# ATSAMG54G19 device description
Architecture: CORTEX-M4; Family: SAMG; Series: SAMG54
Registers are 32-bit, read-write, no defined reset value unless marked. A register's access mark holds for its fields unless they carry their own. Offsets are from the block's base; [hi:lo] are bit positions.

## MEM2MEM — Memory to Memory
Instances: MEM2MEM 0x40028000
0x00 MEM2MEM_THR — Memory to Memory Transfer Holding Register
  [31:0] THDATA — Transfer Holding Data
0x04 MEM2MEM_MR — Memory to Memory Mode Register
  [1:0] TSIZE — Transfer Size
    0=T_8BIT (The buffer size is defined in byte.); 1=T_16BIT (The buffer size is defined in half-word (16-bit).); 2=T_32BIT (The buffer size is defined in word (32-bit). Default value.)
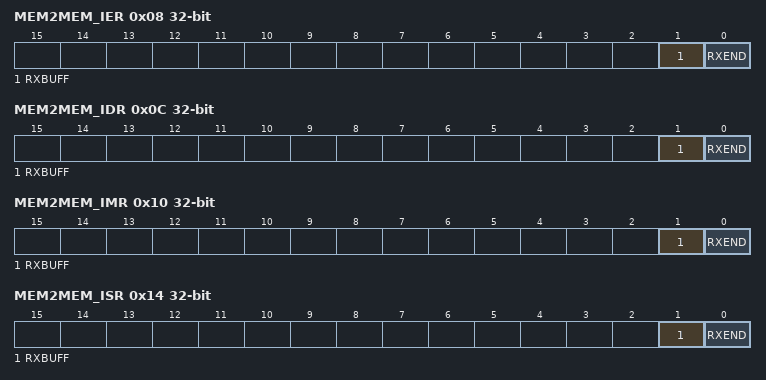
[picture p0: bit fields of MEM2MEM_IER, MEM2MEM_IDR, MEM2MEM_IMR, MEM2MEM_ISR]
0x08 MEM2MEM_IER wo (atomic set of MEM2MEM_IMR) — Memory to Memory Interrupt Enable Register
  [1] RXBUFF — Buffer Full Interrupt Enable
  [0] RXEND — End of Transfer Interrupt Enable
0x0C MEM2MEM_IDR wo (atomic clear of MEM2MEM_IMR) — Memory to Memory Interrupt Disable Register
  [1] RXBUFF — Buffer Full Interrupt Disable
  [0] RXEND — End of Transfer Interrupt Disable
0x10 MEM2MEM_IMR ro (atomic read) — Memory to Memory Interrupt Mask Register
  [1] RXBUFF — Buffer Full Interrupt Mask
  [0] RXEND — End of Transfer Interrupt Mask
0x14 MEM2MEM_ISR ro (atomic read) — Memory to Memory Interrupt Status Register
  [1] RXBUFF — Buffer Full
  [0] RXEND — End of Transfer
0x100 MEM2MEM_RPR — Receive Pointer Register
  [31:0] RXPTR
0x104 MEM2MEM_RCR — Receive Counter Register
  [15:0] RXCTR
0x108 MEM2MEM_TPR — Transmit Pointer Register
  [31:0] TXPTR — Transmit Counter Register
0x10C MEM2MEM_TCR — Transmit Counter Register
  [15:0] TXCTR
0x110 MEM2MEM_RNPR — Receive Next Pointer Register
  [31:0] RXNPTR — Receive Next Pointer
0x114 MEM2MEM_RNCR — Receive Next Counter Register
  [15:0] RXNCTR — Receive Next Counter
0x118 MEM2MEM_TNPR — Transmit Next Pointer Register
  [31:0] TXNPTR — Transmit Next Pointer
0x11C MEM2MEM_TNCR — Transmit Next Counter Register
  [15:0] TXNCTR — Transmit Counter Next
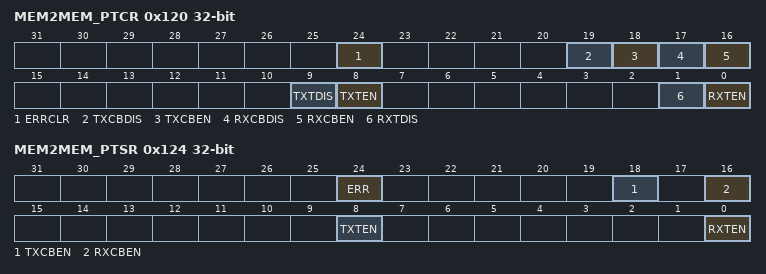
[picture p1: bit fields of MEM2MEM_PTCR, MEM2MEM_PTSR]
0x120 MEM2MEM_PTCR wo — Transfer Control Register
  [24] ERRCLR — Transfer Bus Error Clear
  [19] TXCBDIS — Transmitter Circular Buffer Disable
  [18] TXCBEN — Transmitter Circular Buffer Enable
  [17] RXCBDIS — Receiver Circular Buffer Disable
  [16] RXCBEN — Receiver Circular Buffer Enable
  [9] TXTDIS — Transmitter Transfer Disable
  [8] TXTEN — Transmitter Transfer Enable
  [1] RXTDIS — Receiver Transfer Disable
  [0] RXTEN — Receiver Transfer Enable
0x124 MEM2MEM_PTSR ro — Transfer Status Register
  [24] ERR — Transfer Bus Error
  [18] TXCBEN — Transmitter Circular Buffer Enable
  [16] RXCBEN — Receiver Circular Buffer Enable
  [8] TXTEN — Transmitter Transfer Enable
  [0] RXTEN — Receiver Transfer Enable

## PDC — Peripheral DMA Controller
0x00 PERIPH_RPR — Receive Pointer Register
  [31:0] RXPTR
0x04 PERIPH_RCR — Receive Counter Register
  [15:0] RXCTR
0x08 PERIPH_TPR — Transmit Pointer Register
  [31:0] TXPTR — Transmit Counter Register
0x0C PERIPH_TCR — Transmit Counter Register
  [15:0] TXCTR
0x10 PERIPH_RNPR — Receive Next Pointer Register
  [31:0] RXNPTR — Receive Next Pointer
0x14 PERIPH_RNCR — Receive Next Counter Register
  [15:0] RXNCTR — Receive Next Counter
0x18 PERIPH_TNPR — Transmit Next Pointer Register
  [31:0] TXNPTR — Transmit Next Pointer
0x1C PERIPH_TNCR — Transmit Next Counter Register
  [15:0] TXNCTR — Transmit Counter Next
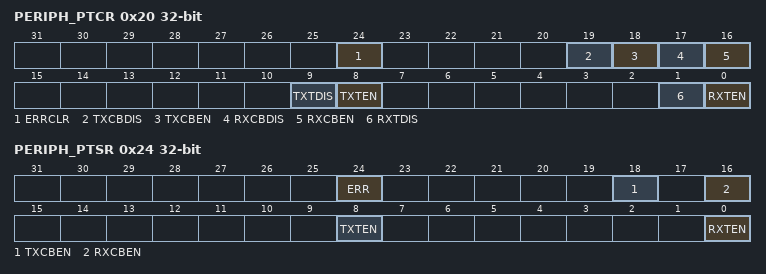
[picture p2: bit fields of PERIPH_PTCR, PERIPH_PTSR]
0x20 PERIPH_PTCR wo — Transfer Control Register
  [24] ERRCLR — Transfer Bus Error Clear
  [19] TXCBDIS — Transmitter Circular Buffer Disable
  [18] TXCBEN — Transmitter Circular Buffer Enable
  [17] RXCBDIS — Receiver Circular Buffer Disable
  [16] RXCBEN — Receiver Circular Buffer Enable
  [9] TXTDIS — Transmitter Transfer Disable
  [8] TXTEN — Transmitter Transfer Enable
  [1] RXTDIS — Receiver Transfer Disable
  [0] RXTEN — Receiver Transfer Enable
0x24 PERIPH_PTSR ro — Transfer Status Register
  [24] ERR — Transfer Bus Error
  [18] TXCBEN — Transmitter Circular Buffer Enable
  [16] RXCBEN — Receiver Circular Buffer Enable
  [8] TXTEN — Transmitter Transfer Enable
  [0] RXTEN — Receiver Transfer Enable

## Notices in the file
Copyright (c) 2017 Microchip Technology Inc.
SPDX-License-Identifier: Apache-2.0
Licensed under the Apache License, Version 2.0 (the "License");
you may not use this file except in compliance with the License.
You may obtain a copy of the License at
http://www.apache.org/licenses/LICENSE-2.0
Unless required by applicable law or agreed to in writing, software
distributed under the License is distributed on an "AS IS" BASIS,
WITHOUT WARRANTIES OR CONDITIONS OF ANY KIND, either express or implied.
See the License for the specific language governing permissions and
limitations under the License.
